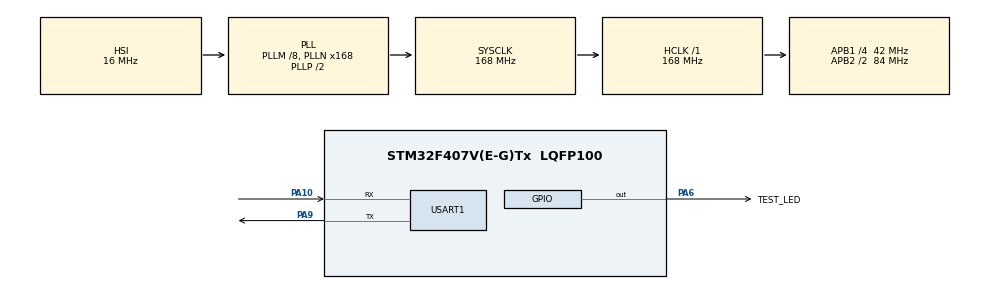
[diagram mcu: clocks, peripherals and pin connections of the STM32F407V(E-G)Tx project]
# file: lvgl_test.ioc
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FREERTOS.Tasks01=defaultTask,24,128,StartDefaultTask,Default,NULL,Dynamic,NULL,NULL
FREERTOS.configCHECK_FOR_STACK_OVERFLOW=2
FREERTOS.configUSE_IDLE_HOOK=1
FREERTOS.configUSE_TICK_HOOK=1
Mcu.Family=STM32F4
Mcu.Name=STM32F407V(E-G)Tx
Mcu.Package=LQFP100
NVIC.PriorityGroup=NVIC_PRIORITYGROUP_4
NVIC.TIM8_UP_TIM13_IRQn=true\:15\:0\:false\:false\:true\:false\:false\:true\:true
NVIC.TimeBase=TIM8_UP_TIM13_IRQn
NVIC.TimeBaseIP=TIM8
NVIC.USART1_IRQn=true\:5\:0\:false\:false\:true\:true\:true\:true\:true
PA10.Mode=Asynchronous
PA10.Signal=USART1_RX
PA13.Mode=Serial_Wire
PA13.Signal=SYS_JTMS-SWDIO
PA14.Mode=Serial_Wire
PA14.Signal=SYS_JTCK-SWCLK
PA6.GPIO_Label=TEST_LED
PA6.GPIO_PuPd=GPIO_PULLUP
PA6.Signal=GPIO_Output
PA9.Mode=Asynchronous
PA9.Signal=USART1_TX
PC14-OSC32_IN.Mode=LSE-External-Oscillator
PC14-OSC32_IN.Signal=RCC_OSC32_IN
PC15-OSC32_OUT.Mode=LSE-External-Oscillator
PC15-OSC32_OUT.Signal=RCC_OSC32_OUT
PH0-OSC_IN.Mode=HSE-External-Oscillator
PH0-OSC_IN.Signal=RCC_OSC_IN
PH1-OSC_OUT.Mode=HSE-External-Oscillator
PH1-OSC_OUT.Signal=RCC_OSC_OUT
ProjectManager.HeapSize=0x200
ProjectManager.StackSize=0x400
ProjectManager.TargetToolchain=MDK-ARM V5.32
RCC.48MHZClocksFreq_Value=84000000
RCC.AHBFreq_Value=168000000
RCC.APB1CLKDivider=RCC_HCLK_DIV4
RCC.APB1Freq_Value=42000000
RCC.APB1TimFreq_Value=84000000
RCC.APB2CLKDivider=RCC_HCLK_DIV2
RCC.APB2Freq_Value=84000000
RCC.APB2TimFreq_Value=168000000
RCC.CortexFreq_Value=168000000
RCC.HCLKFreq_Value=168000000
RCC.HSE_VALUE=25000000
RCC.HSI_VALUE=16000000
RCC.PLLM=8
RCC.PLLN=168
RCC.SYSCLKFreq_VALUE=168000000
RCC.SYSCLKSource=RCC_SYSCLKSOURCE_PLLCLK
RCC.VCOOutputFreq_Value=336000000
USART1.VirtualMode=VM_ASYNC
VP_FREERTOS_VS_CMSIS_V2.Mode=CMSIS_V2
VP_SYS_VS_tim8.Mode=TIM8
board=custom

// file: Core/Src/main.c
/* USER CODE BEGIN Header */
/**
  ******************************************************************************
  * @file           : main.c
  * @brief          : Main program body
  ******************************************************************************
  * @attention
  *
  * Copyright (c) 2026 STMicroelectronics.
  * All rights reserved.
  *
  * This software is licensed under terms that can be found in the LICENSE file
  * in the root directory of this software component.
  * If no LICENSE file comes with this software, it is provided AS-IS.
  *
  ******************************************************************************
  */
/* USER CODE END Header */
#include "main.h"
#include "cmsis_os.h"
#include "usart.h"
#include "gpio.h"

/* USER CODE BEGIN Includes */

#include <stdio.h>
/* USER CODE END Includes */

void SystemClock_Config(void);
void MX_FREERTOS_Init(void);

/* USER CODE BEGIN 0 */
int fputc(int ch,FILE *f){
  //采用轮询方式发送1字节数据，超时时间设置为无限等待
  HAL_UART_Transmit(&huart1,(uint8_t *)&ch,1,HAL_MAX_DELAY);
  return ch;

}
/* USER CODE END 0 */

int main(void)
{

  /* MCU Configuration--------------------------------------------------------*/

  /* Reset of all peripherals, Initializes the Flash interface and the Systick. */
  HAL_Init();

  /* Configure the system clock */
  SystemClock_Config();

  /* Initialize all configured peripherals */
  MX_GPIO_Init();
  MX_USART1_UART_Init();

  /* Init scheduler */
  osKernelInitialize();

  /* Call init function for freertos objects (in cmsis_os2.c) */
  MX_FREERTOS_Init();

  /* Start scheduler */
  osKernelStart();

  /* We should never get here as control is now taken by the scheduler */

  /* Infinite loop */
  while (1)
  {

  }
}

void SystemClock_Config(void)
{
  RCC_OscInitTypeDef RCC_OscInitStruct = {0};
  RCC_ClkInitTypeDef RCC_ClkInitStruct = {0};

  /** Configure the main internal regulator output voltage
  */
  __HAL_RCC_PWR_CLK_ENABLE();
  __HAL_PWR_VOLTAGESCALING_CONFIG(PWR_REGULATOR_VOLTAGE_SCALE1);

  /** Initializes the RCC Oscillators according to the specified parameters
  * in the RCC_OscInitTypeDef structure.
  */
  RCC_OscInitStruct.OscillatorType = RCC_OSCILLATORTYPE_HSI;
  RCC_OscInitStruct.HSIState = RCC_HSI_ON;
  RCC_OscInitStruct.HSICalibrationValue = RCC_HSICALIBRATION_DEFAULT;
  RCC_OscInitStruct.PLL.PLLState = RCC_PLL_ON;
  RCC_OscInitStruct.PLL.PLLSource = RCC_PLLSOURCE_HSI;
  RCC_OscInitStruct.PLL.PLLM = 8;
  RCC_OscInitStruct.PLL.PLLN = 168;
  RCC_OscInitStruct.PLL.PLLP = RCC_PLLP_DIV2;
  RCC_OscInitStruct.PLL.PLLQ = 4;
  if (HAL_RCC_OscConfig(&RCC_OscInitStruct) != HAL_OK)
  {
    Error_Handler();
  }

  /** Initializes the CPU, AHB and APB buses clocks
  */
  RCC_ClkInitStruct.ClockType = RCC_CLOCKTYPE_HCLK|RCC_CLOCKTYPE_SYSCLK
                              |RCC_CLOCKTYPE_PCLK1|RCC_CLOCKTYPE_PCLK2;
  RCC_ClkInitStruct.SYSCLKSource = RCC_SYSCLKSOURCE_PLLCLK;
  RCC_ClkInitStruct.AHBCLKDivider = RCC_SYSCLK_DIV1;
  RCC_ClkInitStruct.APB1CLKDivider = RCC_HCLK_DIV4;
  RCC_ClkInitStruct.APB2CLKDivider = RCC_HCLK_DIV2;

  if (HAL_RCC_ClockConfig(&RCC_ClkInitStruct, FLASH_LATENCY_5) != HAL_OK)
  {
    Error_Handler();
  }
}

void HAL_TIM_PeriodElapsedCallback(TIM_HandleTypeDef *htim)
{
  if (htim->Instance == TIM8) {
    HAL_IncTick();
  }
}

void Error_Handler(void)
{
  __disable_irq();
  while (1)
  {
  }
}

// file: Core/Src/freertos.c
/* USER CODE BEGIN Header */
/**
  ******************************************************************************
  * File Name          : freertos.c
  * Description        : Code for freertos applications
  ******************************************************************************
  * @attention
  *
  * Copyright (c) 2026 STMicroelectronics.
  * All rights reserved.
  *
  * This software is licensed under terms that can be found in the LICENSE file
  * in the root directory of this software component.
  * If no LICENSE file comes with this software, it is provided AS-IS.
  *
  ******************************************************************************
  */
/* USER CODE END Header */

#include "FreeRTOS.h"
#include "task.h"
#include "main.h"
#include "cmsis_os.h"

/* USER CODE BEGIN Includes */
#include <stdio.h>
/* USER CODE END Includes */

/* Definitions for defaultTask */
osThreadId_t defaultTaskHandle;
const osThreadAttr_t defaultTask_attributes = {
  .name = "defaultTask",
  .stack_size = 128 * 4,
  .priority = (osPriority_t) osPriorityNormal,
};

/* USER CODE BEGIN FunctionPrototypes */
TaskHandle_t test_handle;

/* USER CODE END FunctionPrototypes */

void StartDefaultTask(void *argument);

void MX_FREERTOS_Init(void); /* (MISRA C 2004 rule 8.1) */

/* Hook prototypes */
void vApplicationIdleHook(void);
void vApplicationTickHook(void);
void vApplicationStackOverflowHook(xTaskHandle xTask, signed char *pcTaskName);

/* USER CODE BEGIN 2 */
  void test_stack_overflow(void* argument);
void vApplicationIdleHook( void )
{
   /* vApplicationIdleHook() will only be called if configUSE_IDLE_HOOK is set
   to 1 in FreeRTOSConfig.h. It will be called on each iteration of the idle
   task. It is essential that code added to this hook function never attempts
   to block in any way (for example, call xQueueReceive() with a block time
   specified, or call vTaskDelay()). If the application makes use of the
   vTaskDelete() API function (as this demo application does) then it is also
   important that vApplicationIdleHook() is permitted to return to its calling
   function, because it is the responsibility of the idle task to clean up
   memory allocated by the kernel to any task that has since been deleted. */
}
/* USER CODE END 2 */

/* USER CODE BEGIN 3 */
void vApplicationTickHook( void )
{
   /* This function will be called by each tick interrupt if
   configUSE_TICK_HOOK is set to 1 in FreeRTOSConfig.h. User code can be
   added here, but the tick hook is called from an interrupt context, so
   code must not attempt to block, and only the interrupt safe FreeRTOS API
   functions can be used (those that end in FromISR()). */
}
/* USER CODE END 3 */

/* USER CODE BEGIN 4 */
void vApplicationStackOverflowHook(xTaskHandle xTask, signed char *pcTaskName)
{
   /* Run time stack overflow checking is performed if
   configCHECK_FOR_STACK_OVERFLOW is defined to 1 or 2. This hook function is
   called if a stack overflow is detected. */
  while(1){
     printf("Error: Stack overflow in task: %s\r\n", pcTaskName);
     vTaskDelay(1000);
  }

}
/* USER CODE END 4 */

void MX_FREERTOS_Init(void) {

  /* Create the thread(s) */
  /* creation of defaultTask */
  defaultTaskHandle = osThreadNew(StartDefaultTask, NULL, &defaultTask_attributes);

  /* USER CODE BEGIN RTOS_THREADS */
  /* add threads, ... */
  xTaskCreate(test_stack_overflow, "SOF", 256, NULL, osPriorityHigh, &test_handle);

  /* USER CODE END RTOS_THREADS */

}

void StartDefaultTask(void *argument)
{
  /* USER CODE BEGIN StartDefaultTask */
  /* Infinite loop */
  for(;;)
  {

    HAL_GPIO_WritePin(TEST_LED_GPIO_Port, TEST_LED_Pin, GPIO_PIN_SET);
    vTaskDelay(1000);
    HAL_GPIO_WritePin(TEST_LED_GPIO_Port, TEST_LED_Pin, GPIO_PIN_RESET);
    vTaskDelay(1000);
  }
  /* USER CODE END StartDefaultTask */
}

/* USER CODE BEGIN Application */
  void f(void){
    vTaskDelay(200);

    printf("%s          %d\r\n", pcTaskGetTaskName(test_handle), uxTaskGetStackHighWaterMark(test_handle));
    f();

        // --- 加这一句 ---
    // volatile 关键字防止被优化掉，强制函数必须返回来执行这个指令
    volatile int dummy = 0;
    (void)dummy;
  }

  void test_stack_overflow(void* argument){
    // while(1){
    //   printf("Stack overflow test task running...\r\n");
    //   vTaskDelay(1000);
    // }
    f();
  }

/* USER CODE END Application */
